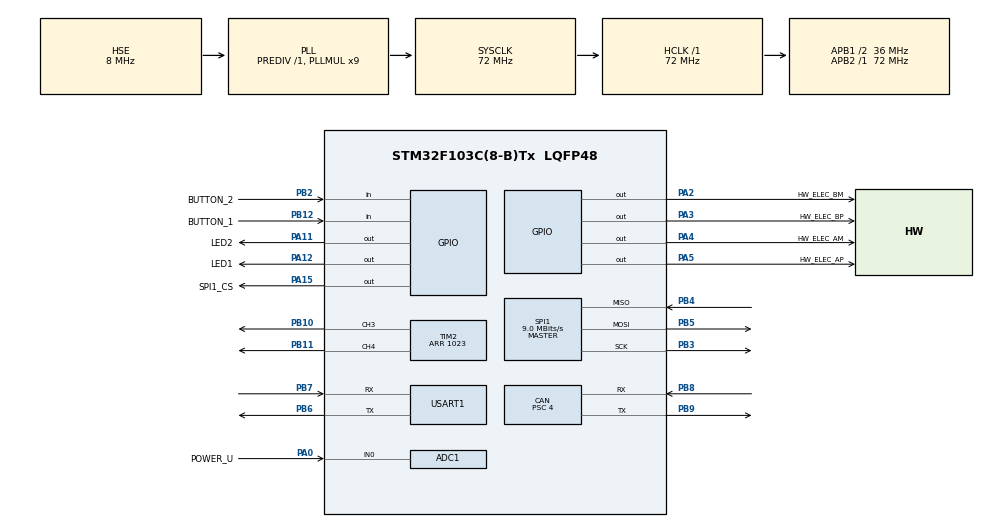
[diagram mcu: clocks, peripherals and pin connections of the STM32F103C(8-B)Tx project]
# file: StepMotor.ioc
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ADC1.Channel-0\#ChannelRegularConversion=ADC_CHANNEL_0
ADC1.ContinuousConvMode=ENABLE
ADC1.NbrOfConversion=1
ADC1.NbrOfConversionFlag=1
ADC1.Rank-0\#ChannelRegularConversion=1
ADC1.SamplingTime-0\#ChannelRegularConversion=ADC_SAMPLETIME_239CYCLES_5
ADC1.master=1
CAN.AWUM=ENABLE
CAN.BS1=CAN_BS1_5TQ
CAN.BS2=CAN_BS2_4TQ
CAN.CalculateBaudRate=900000
CAN.CalculateTimeBit=1111
CAN.CalculateTimeQuantum=111.11111111111111
CAN.Prescaler=4
CAN.TXFP=DISABLE
Dma.ADC1.0.Direction=DMA_PERIPH_TO_MEMORY
Dma.ADC1.0.Instance=DMA1_Channel1
Dma.ADC1.0.MemDataAlignment=DMA_MDATAALIGN_HALFWORD
Dma.ADC1.0.MemInc=DMA_MINC_ENABLE
Dma.ADC1.0.Mode=DMA_CIRCULAR
Dma.ADC1.0.PeriphDataAlignment=DMA_PDATAALIGN_HALFWORD
Dma.ADC1.0.PeriphInc=DMA_PINC_DISABLE
Dma.ADC1.0.Priority=DMA_PRIORITY_MEDIUM
Dma.Request0=ADC1
Dma.Request1=USART1_TX
Dma.Request2=USART1_RX
Dma.USART1_RX.2.Direction=DMA_PERIPH_TO_MEMORY
Dma.USART1_RX.2.Instance=DMA1_Channel5
Dma.USART1_RX.2.MemDataAlignment=DMA_MDATAALIGN_BYTE
Dma.USART1_RX.2.MemInc=DMA_MINC_ENABLE
Dma.USART1_RX.2.Mode=DMA_CIRCULAR
Dma.USART1_RX.2.PeriphDataAlignment=DMA_PDATAALIGN_BYTE
Dma.USART1_RX.2.PeriphInc=DMA_PINC_DISABLE
Dma.USART1_RX.2.Priority=DMA_PRIORITY_VERY_HIGH
Dma.USART1_TX.1.Direction=DMA_MEMORY_TO_PERIPH
Dma.USART1_TX.1.Instance=DMA1_Channel4
Dma.USART1_TX.1.MemDataAlignment=DMA_MDATAALIGN_BYTE
Dma.USART1_TX.1.MemInc=DMA_MINC_ENABLE
Dma.USART1_TX.1.Mode=DMA_NORMAL
Dma.USART1_TX.1.PeriphDataAlignment=DMA_PDATAALIGN_BYTE
Dma.USART1_TX.1.PeriphInc=DMA_PINC_DISABLE
Dma.USART1_TX.1.Priority=DMA_PRIORITY_HIGH
Mcu.Family=STM32F1
Mcu.Name=STM32F103C(8-B)Tx
Mcu.Package=LQFP48
NVIC.CAN1_RX1_IRQn=true\:3\:0\:true\:false\:true\:true\:true\:true
NVIC.CAN1_SCE_IRQn=true\:3\:0\:true\:false\:true\:true\:true\:true
NVIC.DMA1_Channel1_IRQn=true\:0\:0\:false\:false\:true\:false\:true\:true
NVIC.DMA1_Channel4_IRQn=true\:3\:0\:true\:false\:true\:false\:true\:true
NVIC.DMA1_Channel5_IRQn=true\:3\:0\:true\:false\:true\:false\:true\:true
NVIC.PriorityGroup=NVIC_PRIORITYGROUP_4
NVIC.TIM1_UP_IRQn=true\:0\:0\:false\:false\:true\:true\:true\:true
NVIC.TIM4_IRQn=true\:0\:0\:false\:false\:true\:true\:true\:true
NVIC.USART1_IRQn=true\:3\:0\:true\:false\:true\:true\:true\:true
NVIC.USB_HP_CAN1_TX_IRQn=true\:3\:0\:true\:false\:true\:true\:true\:true
NVIC.USB_LP_CAN1_RX0_IRQn=true\:3\:0\:true\:false\:true\:true\:true\:true
PA0-WKUP.GPIO_Label=POWER_U
PA0-WKUP.Signal=ADCx_IN0
PA11.GPIO_Label=LED2
PA11.Signal=GPIO_Output
PA12.GPIO_Label=LED1
PA12.Signal=GPIO_Output
PA13.Mode=Serial_Wire
PA13.Signal=SYS_JTMS-SWDIO
PA14.Mode=Serial_Wire
PA14.Signal=SYS_JTCK-SWCLK
PA15.GPIO_Label=SPI1_CS
PA15.Signal=GPIO_Output
PA2.GPIO_Label=HW_ELEC_BM
PA2.Signal=GPIO_Output
PA3.GPIO_Label=HW_ELEC_BP
PA3.Signal=GPIO_Output
PA4.GPIO_Label=HW_ELEC_AM
PA4.Signal=GPIO_Output
PA5.GPIO_Label=HW_ELEC_AP
PA5.Signal=GPIO_Output
PB10.Signal=S_TIM2_CH3
PB11.Signal=S_TIM2_CH4
PB12.GPIO_Label=BUTTON_1
PB12.Signal=GPIO_Input
PB2.GPIO_Label=BUTTON_2
PB2.Signal=GPIO_Input
PB3.Mode=Full_Duplex_Master
PB3.Signal=SPI1_SCK
PB4.Mode=Full_Duplex_Master
PB4.Signal=SPI1_MISO
PB5.Mode=Full_Duplex_Master
PB5.Signal=SPI1_MOSI
PB6.Mode=Asynchronous
PB6.Signal=USART1_TX
PB7.Mode=Asynchronous
PB7.Signal=USART1_RX
PB8.Mode=CAN_Activate
PB8.Signal=CAN_RX
PB9.Mode=CAN_Activate
PB9.Signal=CAN_TX
PD0-OSC_IN.Mode=HSE-External-Oscillator
PD0-OSC_IN.Signal=RCC_OSC_IN
PD1-OSC_OUT.Mode=HSE-External-Oscillator
PD1-OSC_OUT.Signal=RCC_OSC_OUT
ProjectManager.HeapSize=0x200
ProjectManager.StackSize=0x400
ProjectManager.TargetToolchain=MDK-ARM V5.32
RCC.ADCPresc=RCC_ADCPCLK2_DIV6
RCC.AHBFreq_Value=72000000
RCC.APB1CLKDivider=RCC_HCLK_DIV2
RCC.APB1Freq_Value=36000000
RCC.APB1TimFreq_Value=72000000
RCC.APB2Freq_Value=72000000
RCC.APB2TimFreq_Value=72000000
RCC.HCLKFreq_Value=72000000
RCC.PLLMUL=RCC_PLL_MUL9
RCC.PLLSourceVirtual=RCC_PLLSOURCE_HSE
RCC.SYSCLKFreq_VALUE=72000000
RCC.SYSCLKSource=RCC_SYSCLKSOURCE_PLLCLK
RCC.USBFreq_Value=72000000
SH.ADCx_IN0.0=ADC1_IN0,IN0
SH.S_TIM2_CH3.0=TIM2_CH3,PWM Generation3 CH3
SH.S_TIM2_CH4.0=TIM2_CH4,PWM Generation4 CH4
SPI1.BaudRatePrescaler=SPI_BAUDRATEPRESCALER_8
SPI1.CLKPhase=SPI_PHASE_2EDGE
SPI1.CLKPolarity=SPI_POLARITY_HIGH
SPI1.CalculateBaudRate=9.0 MBits/s
SPI1.DataSize=SPI_DATASIZE_16BIT
SPI1.Direction=SPI_DIRECTION_2LINES
SPI1.Mode=SPI_MODE_MASTER
SPI1.VirtualType=VM_MASTER
TIM1.AutoReloadPreload=TIM_AUTORELOAD_PRELOAD_ENABLE
TIM1.Period=9999
TIM1.Prescaler=71
TIM2.Channel-PWM\ Generation3\ CH3=TIM_CHANNEL_3
TIM2.Channel-PWM\ Generation4\ CH4=TIM_CHANNEL_4
TIM2.Period=1023
TIM4.AutoReloadPreload=TIM_AUTORELOAD_PRELOAD_ENABLE
TIM4.Period=49
TIM4.Prescaler=71
USART1.VirtualMode=VM_ASYNC
VP_TIM1_VS_ClockSourceINT.Mode=Internal
VP_TIM4_VS_ClockSourceINT.Mode=Internal
board=custom

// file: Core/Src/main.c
/* USER CODE BEGIN Header */
/**
  ******************************************************************************
  * @file           : main.c
  * @brief          : Main program body
  ******************************************************************************
  * @attention
  *
  * <h2><center>&copy; Copyright (c) 2026 STMicroelectronics.
  * All rights reserved.</center></h2>
  *
  * This software component is licensed by ST under BSD 3-Clause license,
  * the "License"; You may not use this file except in compliance with the
  * License. You may obtain a copy of the License at:
  *                        opensource.org/licenses/BSD-3-Clause
  *
  ******************************************************************************
  */
/* USER CODE END Header */
#include "main.h"
#include "adc.h"
#include "can.h"
#include "dma.h"
#include "spi.h"
#include "tim.h"
#include "usart.h"
#include "gpio.h"

/* USER CODE BEGIN Includes */
#include "elaco_main.h"
/* USER CODE END Includes */

void SystemClock_Config(void);

int main(void)
{

  /* MCU Configuration--------------------------------------------------------*/

  /* Reset of all peripherals, Initializes the Flash interface and the Systick. */
  HAL_Init();

  /* Configure the system clock */
  SystemClock_Config();

  /* Initialize all configured peripherals */
  MX_GPIO_Init();
  MX_DMA_Init();
  MX_ADC1_Init();
  MX_USART1_UART_Init();
  MX_CAN_Init();
  MX_SPI1_Init();
  MX_TIM1_Init();
  MX_TIM2_Init();
  MX_TIM4_Init();
  /* USER CODE BEGIN 2 */

  elaco_main();

  /* USER CODE END 2 */

  /* Infinite loop */
  /* USER CODE BEGIN WHILE */
  /* elaco_main() 接管了主循环，不会返回此处 */
    /* USER CODE END WHILE */

  while (1)
  {
  }
}

void SystemClock_Config(void)
{
  RCC_OscInitTypeDef RCC_OscInitStruct = {0};
  RCC_ClkInitTypeDef RCC_ClkInitStruct = {0};
  RCC_PeriphCLKInitTypeDef PeriphClkInit = {0};

  /** Initializes the RCC Oscillators according to the specified parameters
  * in the RCC_OscInitTypeDef structure.
  */
  RCC_OscInitStruct.OscillatorType = RCC_OSCILLATORTYPE_HSE;
  RCC_OscInitStruct.HSEState = RCC_HSE_ON;
  RCC_OscInitStruct.HSEPredivValue = RCC_HSE_PREDIV_DIV1;
  RCC_OscInitStruct.HSIState = RCC_HSI_ON;
  RCC_OscInitStruct.PLL.PLLState = RCC_PLL_ON;
  RCC_OscInitStruct.PLL.PLLSource = RCC_PLLSOURCE_HSE;
  RCC_OscInitStruct.PLL.PLLMUL = RCC_PLL_MUL9;
  if (HAL_RCC_OscConfig(&RCC_OscInitStruct) != HAL_OK)
  {
    Error_Handler();
  }
  /** Initializes the CPU, AHB and APB buses clocks
  */
  RCC_ClkInitStruct.ClockType = RCC_CLOCKTYPE_HCLK|RCC_CLOCKTYPE_SYSCLK
                              |RCC_CLOCKTYPE_PCLK1|RCC_CLOCKTYPE_PCLK2;
  RCC_ClkInitStruct.SYSCLKSource = RCC_SYSCLKSOURCE_PLLCLK;
  RCC_ClkInitStruct.AHBCLKDivider = RCC_SYSCLK_DIV1;
  RCC_ClkInitStruct.APB1CLKDivider = RCC_HCLK_DIV2;
  RCC_ClkInitStruct.APB2CLKDivider = RCC_HCLK_DIV1;

  if (HAL_RCC_ClockConfig(&RCC_ClkInitStruct, FLASH_LATENCY_2) != HAL_OK)
  {
    Error_Handler();
  }
  PeriphClkInit.PeriphClockSelection = RCC_PERIPHCLK_ADC;
  PeriphClkInit.AdcClockSelection = RCC_ADCPCLK2_DIV6;
  if (HAL_RCCEx_PeriphCLKConfig(&PeriphClkInit) != HAL_OK)
  {
    Error_Handler();
  }
}

void Error_Handler(void)
{
  __disable_irq();
  while (1)
  {
  }
}

/************************ (C) COPYRIGHT STMicroelectronics *****END OF FILE****/
